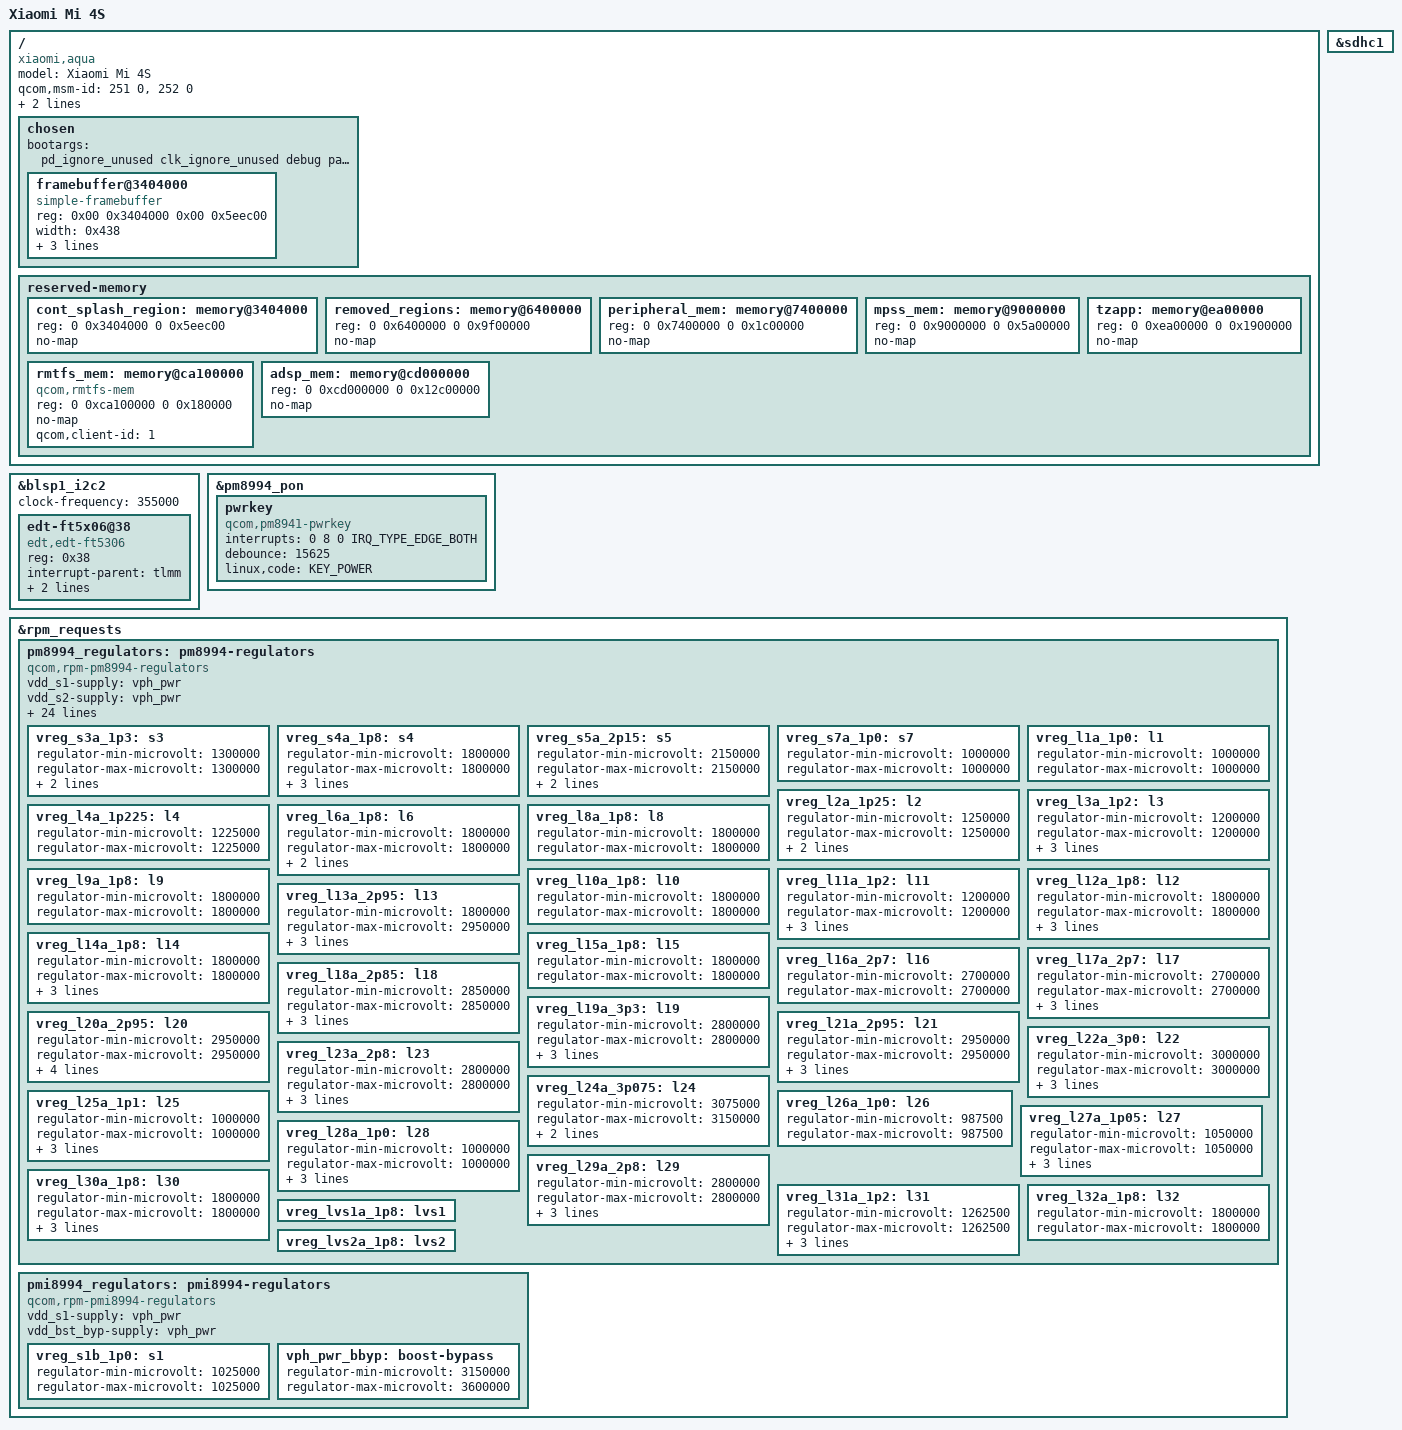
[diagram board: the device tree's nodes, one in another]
// SPDX-License-Identifier: BSD-3-Clause
/*
 * Copyright (c) 2020, Xilin Wu <strongtz@yeah.net>
 */

/dts-v1/;

#include "msm8994.dtsi"
#include "pm8994.dtsi"
#include "pmi8994.dtsi"
#include <dt-bindings/gpio/gpio.h>
#include <dt-bindings/input/gpio-keys.h>
#include <dt-bindings/pinctrl/qcom,pmic-gpio.h>

/delete-node/ &rmtfs_mem;
/delete-node/ &mpss_mem;
/delete-node/ &adsp_mem;

/ {
	model = "Xiaomi Mi 4S";
	compatible = "xiaomi,aqua", "qcom,msm8992";
	qcom,msm-id = <251 0>, <252 0>;
	qcom,pmic-id = <0x10009 0x1000a 0x00 0x00>;
	qcom,board-id = <0x1e 0x00>;

	chosen {
		bootargs = "pd_ignore_unused clk_ignore_unused debug panic=30";

		#address-cells = <2>;
		#size-cells = <2>;
		ranges;

		framebuffer@3404000 {
			status = "okay";
			compatible = "simple-framebuffer";
			reg = <0x00 0x3404000 0x00 0x5eec00>;
			width = <0x438>;
			height = <0x780>;
			stride = <0xca8>;
			format = "r8g8b8";
		};

	};

	// clocks {
	// 	compatible = "simple-bus";

	// 	divclk4: divclk4 {
	// 		compatible = "fixed-clock";
	// 		#clock-cells = <0>;

	// 		clock-frequency = <32768>;
	// 		clock-output-names = "divclk4";

	// 		pinctrl-names = "default";
	// 		pinctrl-0 = <&divclk4_pin_a>;
	// 	};
	// };

	// gpio-keys {
	// 	compatible = "gpio-keys";
	// 	input-name = "gpio-keys";
	// 	autorepeat;

	// 	volupkey {
	// 		label = "Volume Up";
	// 		gpios = <&pm8994_gpios 3 GPIO_ACTIVE_LOW>;
	// 		linux,input-type = <1>;
	// 		linux,code = <KEY_VOLUMEUP>;
	// 		wakeup-source;
	// 		debounce-interval = <15>;
	// 	};
	// };

	reserved-memory {

		cont_splash_region: memory@3404000 {
			// compatible = "removed-dma-pool";
			reg = <0 0x3404000 0 0x5eec00>;
			no-map;
		};

		removed_regions: memory@6400000 {
			reg = <0 0x6400000 0 0x9f00000>;
			no-map;
		};

		peripheral_mem: memory@7400000 {
			reg = <0 0x7400000 0 0x1c00000>;
			no-map;
		};

		mpss_mem: memory@9000000 {
			reg = <0 0x9000000 0 0x5a00000>;
			no-map;
		};

		tzapp: memory@ea00000 {
			reg = <0 0xea00000 0 0x1900000>;
			no-map;
		};

		rmtfs_mem: memory@ca100000 {
			compatible = "qcom,rmtfs-mem";
			reg = <0 0xca100000 0 0x180000>;
			no-map;

			qcom,client-id = <1>;
		};

		adsp_mem: memory@cd000000 {
			reg = <0 0xcd000000 0 0x12c00000>;
			no-map;
		};

	};
};

&blsp1_i2c2 {
	status = "okay";
	clock-frequency = <355000>;

	/* Touch */

	edt-ft5x06@38 {
        compatible = "edt,edt-ft5306";
        reg = <0x38>;
        interrupt-parent = <&tlmm>;
        interrupts = <61 0x2008>;
        reset-gpios = <&tlmm 60 0x00>;
        // wake-gpios = <&tlmm 9 GPIO_ACTIVE_HIGH>;
      };
};


// &blsp2_uart2 {
// 	status = "disabled";

// 	qca6174_bt: bluetooth {
// 		compatible = "qcom,qca6174-bt";

// 		enable-gpios = <&pm8994_gpios 19 GPIO_ACTIVE_HIGH>;
// 		clocks = <&divclk4>;
// 	};
// };

// &pm8994_gpios {
// 	bt_en_gpios: bt_en_gpios {
// 		pinconf {
// 			pins = "gpio19";
// 			function = PMIC_GPIO_FUNC_NORMAL;
// 			output-low;
// 			power-source = <PM8994_GPIO_S4>;
// 			qcom,drive-strength = <PMIC_GPIO_STRENGTH_LOW>;
// 			bias-pull-down;
// 		};
// 	};

// 	divclk4_pin_a: divclk4 {
// 		pinconf {
// 			pins = "gpio18";
// 			function = PMIC_GPIO_FUNC_FUNC2;
// 			power-source = <PM8994_GPIO_S4>;
// 			bias-disable;
// 		};
// 	};
// };

&pm8994_pon {
	pwrkey {
		compatible = "qcom,pm8941-pwrkey";
		interrupts = <0 8 0 IRQ_TYPE_EDGE_BOTH>;
		debounce = <15625>;
		linux,code = <KEY_POWER>;
	};

	// volwnkey {
	// 	compatible = "qcom,pm8941-resin";
	// 	interrupts = <0 8 1 IRQ_TYPE_EDGE_BOTH>;
	// 	debounce = <15625>;
	// 	linux,code = <KEY_VOLUMEDOWN>;
	// };
};

// &pmi8994_spmi_regulators {
// 	vdd_gfx: s2@1700 {
// 		reg = <0x1700 0x100>;
// 		regulator-min-microvolt = <980000>;
// 		regulator-max-microvolt = <980000>;
// 	};
// };

&rpm_requests {
	pm8994_regulators: pm8994-regulators {
		compatible = "qcom,rpm-pm8994-regulators";

		vdd_s1-supply = <&vph_pwr>;
		vdd_s2-supply = <&vph_pwr>;
		vdd_s3-supply = <&vph_pwr>;
		vdd_s4-supply = <&vph_pwr>;
		vdd_s5-supply = <&vph_pwr>;
		vdd_s6-supply = <&vph_pwr>;
		vdd_s7-supply = <&vph_pwr>;
		vdd_s8-supply = <&vph_pwr>;
		vdd_s9-supply = <&vph_pwr>;
		vdd_s10-supply = <&vph_pwr>;
		vdd_s11-supply = <&vph_pwr>;
		vdd_s12-supply = <&vph_pwr>;
		vdd_l1-supply = <&vreg_s1b_1p0>;
		vdd_l2_l26_l28-supply = <&vreg_s3a_1p3>;
		vdd_l3_l11-supply = <&vreg_s3a_1p3>;
		vdd_l4_l27_l31-supply = <&vreg_s3a_1p3>;
		vdd_l5_l7-supply = <&vreg_s5a_2p15>;
		vdd_l6_l12_l32-supply = <&vreg_s5a_2p15>;
		vdd_l8_l16_l30-supply = <&vph_pwr>;
		vdd_l9_l10_l18_l22-supply = <&vph_pwr_bbyp>;
		vdd_l13_l19_l23_l24-supply = <&vph_pwr_bbyp>;
		vdd_l14_l15-supply = <&vreg_s5a_2p15>;
		vdd_l17_l29-supply = <&vph_pwr_bbyp>;
		vdd_l20_l21-supply = <&vph_pwr_bbyp>;
		vdd_l25-supply = <&vreg_s5a_2p15>;
		vdd_lvs1_2-supply = <&vreg_s4a_1p8>;

		/* S1, S2, S6 and S12 are managed by RPMPD */

		vreg_s3a_1p3: s3 {
			regulator-min-microvolt = <1300000>;
			regulator-max-microvolt = <1300000>;
			regulator-allow-set-load;
			regulator-system-load = <300000>;
		};

		vreg_s4a_1p8: s4 {
			regulator-min-microvolt = <1800000>;
			regulator-max-microvolt = <1800000>;
			regulator-allow-set-load;
			regulator-always-on;
			regulator-system-load = <325000>;
		};

		vreg_s5a_2p15: s5 {
			regulator-min-microvolt = <2150000>;
			regulator-max-microvolt = <2150000>;
			regulator-allow-set-load;
			regulator-system-load = <325000>;
		};

		vreg_s7a_1p0: s7 {
			regulator-min-microvolt = <1000000>;
			regulator-max-microvolt = <1000000>;
		};

		/*
		 * S8 - SPMI-managed VDD_APC0
		 * S9, S10 and S11 (the main one) - SPMI-managed VDD_APC1
		 */

		vreg_l1a_1p0: l1 {
			regulator-min-microvolt = <1000000>;
			regulator-max-microvolt = <1000000>;
		};

		vreg_l2a_1p25: l2 {
			regulator-min-microvolt = <1250000>;
			regulator-max-microvolt = <1250000>;
			regulator-allow-set-load;
			regulator-system-load = <4160>;
		};

		vreg_l3a_1p2: l3 {
			regulator-min-microvolt = <1200000>;
			regulator-max-microvolt = <1200000>;
			regulator-always-on;
			regulator-allow-set-load;
			regulator-system-load = <80000>;
		};

		vreg_l4a_1p225: l4 {
			regulator-min-microvolt = <1225000>;
			regulator-max-microvolt = <1225000>;
		};

		/* L5 is inaccessible from RPM */

		vreg_l6a_1p8: l6 {
			regulator-min-microvolt = <1800000>;
			regulator-max-microvolt = <1800000>;
			regulator-allow-set-load;
			regulator-system-load = <1000>;
		};

		/* L7 is inaccessible from RPM */

		vreg_l8a_1p8: l8 {
			regulator-min-microvolt = <1800000>;
			regulator-max-microvolt = <1800000>;
		};

		vreg_l9a_1p8: l9 {
			regulator-min-microvolt = <1800000>;
			regulator-max-microvolt = <1800000>;
		};

		vreg_l10a_1p8: l10 {
			regulator-min-microvolt = <1800000>;
			regulator-max-microvolt = <1800000>;
		};

		vreg_l11a_1p2: l11 {
			regulator-min-microvolt = <1200000>;
			regulator-max-microvolt = <1200000>;
			regulator-always-on;
			regulator-allow-set-load;
			regulator-system-load = <35000>;
		};

		vreg_l12a_1p8: l12 {
			regulator-min-microvolt = <1800000>;
			regulator-max-microvolt = <1800000>;
			regulator-always-on;
			regulator-allow-set-load;
			regulator-system-load = <50000>;
		};

		vreg_l13a_2p95: l13 {
			regulator-min-microvolt = <1800000>;
			regulator-max-microvolt = <2950000>;
			regulator-always-on;
			regulator-allow-set-load;
			regulator-system-load = <22000>;
		};

		vreg_l14a_1p8: l14 {
			regulator-min-microvolt = <1800000>;
			regulator-max-microvolt = <1800000>;
			regulator-always-on;
			regulator-allow-set-load;
			regulator-system-load = <52000>;
		};

		vreg_l15a_1p8: l15 {
			regulator-min-microvolt = <1800000>;
			regulator-max-microvolt = <1800000>;
		};

		vreg_l16a_2p7: l16 {
			regulator-min-microvolt = <2700000>;
			regulator-max-microvolt = <2700000>;
		};

		vreg_l17a_2p7: l17 {
			regulator-min-microvolt = <2700000>;
			regulator-max-microvolt = <2700000>;
			regulator-always-on;
			regulator-allow-set-load;
			regulator-system-load = <300000>;
		};

		vreg_l18a_2p85: l18 {
			regulator-min-microvolt = <2850000>;
			regulator-max-microvolt = <2850000>;
			regulator-always-on;
			regulator-allow-set-load;
			regulator-system-load = <600000>;
		};

		vreg_l19a_3p3: l19 {
			regulator-min-microvolt = <2800000>;
			regulator-max-microvolt = <2800000>;
			regulator-always-on;
			regulator-allow-set-load;
			regulator-system-load = <500000>;
		};

		vreg_l20a_2p95: l20 {
			regulator-min-microvolt = <2950000>;
			regulator-max-microvolt = <2950000>;
			regulator-always-on;
			regulator-boot-on;
			regulator-allow-set-load;
			regulator-system-load = <570000>;
		};

		vreg_l21a_2p95: l21 {
			regulator-min-microvolt = <2950000>;
			regulator-max-microvolt = <2950000>;
			regulator-always-on;
			regulator-allow-set-load;
			regulator-system-load = <800000>;
		};

		vreg_l22a_3p0: l22 {
			regulator-min-microvolt = <3000000>;
			regulator-max-microvolt = <3000000>;
			regulator-always-on;
			regulator-allow-set-load;
			regulator-system-load = <150000>;
		};

		vreg_l23a_2p8: l23 {
			regulator-min-microvolt = <2800000>;
			regulator-max-microvolt = <2800000>;
			regulator-always-on;
			regulator-allow-set-load;
			regulator-system-load = <80000>;
		};

		vreg_l24a_3p075: l24 {
			regulator-min-microvolt = <3075000>;
			regulator-max-microvolt = <3150000>;
			regulator-allow-set-load;
			regulator-system-load = <5800>;
		};

		vreg_l25a_1p1: l25 {
			regulator-min-microvolt = <1000000>;
			regulator-max-microvolt = <1000000>;
			regulator-always-on;
			regulator-allow-set-load;
			regulator-system-load = <80000>;
		};

		vreg_l26a_1p0: l26 {
			regulator-min-microvolt = <987500>;
			regulator-max-microvolt = <987500>;
		};

		vreg_l27a_1p05: l27 {
			regulator-min-microvolt = <1050000>;
			regulator-max-microvolt = <1050000>;
			regulator-always-on;
			regulator-allow-set-load;
			regulator-system-load = <500000>;
		};

		vreg_l28a_1p0: l28 {
			regulator-min-microvolt = <1000000>;
			regulator-max-microvolt = <1000000>;
			regulator-always-on;
			regulator-allow-set-load;
			regulator-system-load = <26000>;
		};

		vreg_l29a_2p8: l29 {
			regulator-min-microvolt = <2800000>;
			regulator-max-microvolt = <2800000>;
			regulator-always-on;
			regulator-allow-set-load;
			regulator-system-load = <80000>;
		};

		vreg_l30a_1p8: l30 {
			regulator-min-microvolt = <1800000>;
			regulator-max-microvolt = <1800000>;
			regulator-always-on;
			regulator-allow-set-load;
			regulator-system-load = <2500>;
		};

		vreg_l31a_1p2: l31 {
			regulator-min-microvolt = <1262500>;
			regulator-max-microvolt = <1262500>;
			regulator-always-on;
			regulator-allow-set-load;
			regulator-system-load = <600000>;
		};

		vreg_l32a_1p8: l32 {
			regulator-min-microvolt = <1800000>;
			regulator-max-microvolt = <1800000>;
		};

		vreg_lvs1a_1p8: lvs1 { };

		vreg_lvs2a_1p8: lvs2 { };
	};

	pmi8994_regulators: pmi8994-regulators {
		compatible = "qcom,rpm-pmi8994-regulators";

		vdd_s1-supply = <&vph_pwr>;
		vdd_bst_byp-supply = <&vph_pwr>;

		vreg_s1b_1p0: s1 {
			regulator-min-microvolt = <1025000>;
			regulator-max-microvolt = <1025000>;
		};

		/* S2 & S3 - VDD_GFX */

		vph_pwr_bbyp: boost-bypass {
			regulator-min-microvolt = <3150000>;
			regulator-max-microvolt = <3600000>;
		};
	};
};

&sdhc1 {
	status = "okay";

};

// &sdhc2 {
// 	status = "okay";

// 	pinctrl-names = "default", "sleep";
// 	pinctrl-0 = <&sdc2_clk_on &sdc2_cmd_on &sdc2_data_on>;
// 	pinctrl-1 = <&sdc2_clk_off &sdc2_cmd_off &sdc2_data_off>;

// 	vmmc-supply = <&vreg_l21a_2p95>;
// 	vqmmc-supply = <&vreg_l13a_2p95>;

// 	cd-gpios = <&pm8994_gpios 8 GPIO_ACTIVE_LOW>;
// };



// &tlmm {
// 	grip_default: grip-default {
// 		pins = "gpio39";
// 		function = "gpio";
// 		drive-strength = <6>;
// 		bias-pull-down;
// 	};

// 	grip_sleep: grip-sleep {
// 		pins = "gpio39";
// 		function = "gpio";
// 		drive-strength = <2>;
// 		bias-pull-down;
// 	};

// 	hall_front_default: hall-front-default {
// 		pins = "gpio42";
// 		function = "gpio";
// 		drive-strength = <2>;
// 		bias-disable;
// 	};

// 	hall_back_default: hall-back-default {
// 		pins = "gpio75";
// 		function = "gpio";
// 		drive-strength = <2>;
// 		bias-disable;
// 	};
// };
